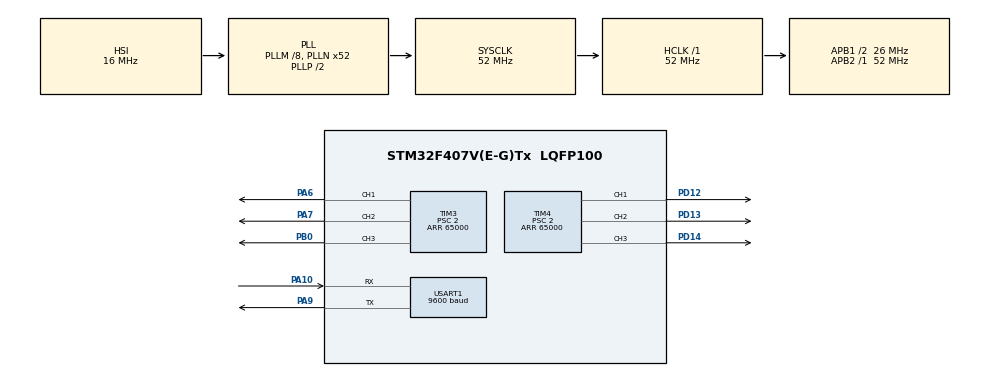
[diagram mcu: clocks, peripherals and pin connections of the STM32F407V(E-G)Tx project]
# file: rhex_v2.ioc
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Mcu.Family=STM32F4
Mcu.Name=STM32F407V(E-G)Tx
Mcu.Package=LQFP100
NVIC.PriorityGroup=NVIC_PRIORITYGROUP_4
PA10.Mode=Asynchronous
PA10.Signal=USART1_RX
PA6.Signal=S_TIM3_CH1
PA7.Signal=S_TIM3_CH2
PA9.Mode=Asynchronous
PA9.Signal=USART1_TX
PB0.Signal=S_TIM3_CH3
PD12.Signal=S_TIM4_CH1
PD13.Signal=S_TIM4_CH2
PD14.Signal=S_TIM4_CH3
PH0-OSC_IN.Mode=HSE-External-Oscillator
PH0-OSC_IN.Signal=RCC_OSC_IN
PH1-OSC_OUT.Mode=HSE-External-Oscillator
PH1-OSC_OUT.Signal=RCC_OSC_OUT
ProjectManager.HeapSize=0x200
ProjectManager.StackSize=0x400
ProjectManager.TargetToolchain=TrueSTUDIO
RCC.48MHZClocksFreq_Value=26000000
RCC.AHBFreq_Value=52000000
RCC.APB1CLKDivider=RCC_HCLK_DIV2
RCC.APB1Freq_Value=26000000
RCC.APB1TimFreq_Value=52000000
RCC.APB2Freq_Value=52000000
RCC.APB2TimFreq_Value=52000000
RCC.CortexFreq_Value=52000000
RCC.HCLKFreq_Value=52000000
RCC.HSE_VALUE=25000000
RCC.HSI_VALUE=16000000
RCC.LSE_VALUE=32768
RCC.PLLM=8
RCC.PLLN=52
RCC.SYSCLKFreq_VALUE=52000000
RCC.SYSCLKSource=RCC_SYSCLKSOURCE_PLLCLK
RCC.VCOOutputFreq_Value=104000000
SH.S_TIM3_CH1.0=TIM3_CH1,PWM Generation1 CH1
SH.S_TIM3_CH2.0=TIM3_CH2,PWM Generation2 CH2
SH.S_TIM3_CH3.0=TIM3_CH3,PWM Generation3 CH3
SH.S_TIM4_CH1.0=TIM4_CH1,PWM Generation1 CH1
SH.S_TIM4_CH2.0=TIM4_CH2,PWM Generation2 CH2
SH.S_TIM4_CH3.0=TIM4_CH3,PWM Generation3 CH3
TIM3.Channel-PWM\ Generation1\ CH1=TIM_CHANNEL_1
TIM3.Channel-PWM\ Generation2\ CH2=TIM_CHANNEL_2
TIM3.Channel-PWM\ Generation3\ CH3=TIM_CHANNEL_3
TIM3.Period=65000
TIM3.Prescaler=2
TIM4.Channel-PWM\ Generation1\ CH1=TIM_CHANNEL_1
TIM4.Channel-PWM\ Generation2\ CH2=TIM_CHANNEL_2
TIM4.Channel-PWM\ Generation3\ CH3=TIM_CHANNEL_3
TIM4.Period=65000
TIM4.Prescaler=2
USART1.BaudRate=9600
USART1.VirtualMode=VM_ASYNC
VP_TIM3_VS_ClockSourceINT.Mode=Internal
VP_TIM4_VS_ClockSourceINT.Mode=Internal
board=rhex_v2

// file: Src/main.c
/**
  ******************************************************************************
  * File Name          : main.c
  * Description        : Main program body
  ******************************************************************************
  ** This notice applies to any and all portions of this file
  * that are not between comment pairs USER CODE BEGIN and
  * USER CODE END. Other portions of this file, whether
  * inserted by the user or by software development tools
  * are owned by their respective copyright owners.
  *
  * COPYRIGHT(c) 2018 STMicroelectronics
  */

#include "main.h"
#include "stm32f4xx_hal.h"
#include "servolib.h"

TIM_HandleTypeDef htim3;
TIM_HandleTypeDef htim4;

UART_HandleTypeDef huart1;

/* USER CODE BEGIN PV */
/* Private variables ---------------------------------------------------------*/

/* USER CODE END PV */

void SystemClock_Config(void);
static void MX_GPIO_Init(void);
static void MX_TIM3_Init(void);
static void MX_TIM4_Init(void);
static void MX_USART1_UART_Init(void);
void HAL_TIM_MspPostInit(TIM_HandleTypeDef *htim);

/* USER CODE BEGIN PFP */
/* Private function prototypes -----------------------------------------------*/

/* USER CODE END PFP */

int main(void)
{

  /* MCU Configuration----------------------------------------------------------*/

  /* Reset of all peripherals, Initializes the Flash interface and the Systick. */
  HAL_Init();

  /* Configure the system clock */
  SystemClock_Config();

  /* Initialize all configured peripherals */
  MX_GPIO_Init();
  MX_TIM3_Init();
  MX_TIM4_Init();
  MX_USART1_UART_Init();

  /* USER CODE BEGIN 2 */

  struct Servos servos;
  initServos(&servos, &htim3, &htim4, 65000);

  /* USER CODE END 2 */

  /* Infinite loop */
  /* USER CODE BEGIN WHILE */
  /* ---------------------------------------------------------- While ---------------------------------------------------------- */
  while (1)
  {
  /* USER CODE END WHILE */

  }

}

/** System Clock Configuration
*/
void SystemClock_Config(void)
{

  RCC_OscInitTypeDef RCC_OscInitStruct;
  RCC_ClkInitTypeDef RCC_ClkInitStruct;

    /**Configure the main internal regulator output voltage
    */
  __HAL_RCC_PWR_CLK_ENABLE();

  __HAL_PWR_VOLTAGESCALING_CONFIG(PWR_REGULATOR_VOLTAGE_SCALE1);

    /**Initializes the CPU, AHB and APB busses clocks
    */
  RCC_OscInitStruct.OscillatorType = RCC_OSCILLATORTYPE_HSI;
  RCC_OscInitStruct.HSIState = RCC_HSI_ON;
  RCC_OscInitStruct.HSICalibrationValue = 16;
  RCC_OscInitStruct.PLL.PLLState = RCC_PLL_ON;
  RCC_OscInitStruct.PLL.PLLSource = RCC_PLLSOURCE_HSI;
  RCC_OscInitStruct.PLL.PLLM = 8;
  RCC_OscInitStruct.PLL.PLLN = 52;
  RCC_OscInitStruct.PLL.PLLP = RCC_PLLP_DIV2;
  RCC_OscInitStruct.PLL.PLLQ = 4;
  if (HAL_RCC_OscConfig(&RCC_OscInitStruct) != HAL_OK)
  {
    _Error_Handler(__FILE__, __LINE__);
  }

    /**Initializes the CPU, AHB and APB busses clocks
    */
  RCC_ClkInitStruct.ClockType = RCC_CLOCKTYPE_HCLK|RCC_CLOCKTYPE_SYSCLK
                              |RCC_CLOCKTYPE_PCLK1|RCC_CLOCKTYPE_PCLK2;
  RCC_ClkInitStruct.SYSCLKSource = RCC_SYSCLKSOURCE_PLLCLK;
  RCC_ClkInitStruct.AHBCLKDivider = RCC_SYSCLK_DIV1;
  RCC_ClkInitStruct.APB1CLKDivider = RCC_HCLK_DIV2;
  RCC_ClkInitStruct.APB2CLKDivider = RCC_HCLK_DIV1;

  if (HAL_RCC_ClockConfig(&RCC_ClkInitStruct, FLASH_LATENCY_1) != HAL_OK)
  {
    _Error_Handler(__FILE__, __LINE__);
  }

    /**Configure the Systick interrupt time
    */
  HAL_SYSTICK_Config(HAL_RCC_GetHCLKFreq()/1000);

    /**Configure the Systick
    */
  HAL_SYSTICK_CLKSourceConfig(SYSTICK_CLKSOURCE_HCLK);

  /* SysTick_IRQn interrupt configuration */
  HAL_NVIC_SetPriority(SysTick_IRQn, 0, 0);
}

/* TIM3 init function */
static void MX_TIM3_Init(void)
{

  TIM_ClockConfigTypeDef sClockSourceConfig;
  TIM_MasterConfigTypeDef sMasterConfig;
  TIM_OC_InitTypeDef sConfigOC;

  htim3.Instance = TIM3;
  htim3.Init.Prescaler = 2;
  htim3.Init.CounterMode = TIM_COUNTERMODE_UP;
  htim3.Init.Period = 65000;
  htim3.Init.ClockDivision = TIM_CLOCKDIVISION_DIV1;
  if (HAL_TIM_Base_Init(&htim3) != HAL_OK)
  {
    _Error_Handler(__FILE__, __LINE__);
  }

  sClockSourceConfig.ClockSource = TIM_CLOCKSOURCE_INTERNAL;
  if (HAL_TIM_ConfigClockSource(&htim3, &sClockSourceConfig) != HAL_OK)
  {
    _Error_Handler(__FILE__, __LINE__);
  }

  if (HAL_TIM_PWM_Init(&htim3) != HAL_OK)
  {
    _Error_Handler(__FILE__, __LINE__);
  }

  sMasterConfig.MasterOutputTrigger = TIM_TRGO_RESET;
  sMasterConfig.MasterSlaveMode = TIM_MASTERSLAVEMODE_DISABLE;
  if (HAL_TIMEx_MasterConfigSynchronization(&htim3, &sMasterConfig) != HAL_OK)
  {
    _Error_Handler(__FILE__, __LINE__);
  }

  sConfigOC.OCMode = TIM_OCMODE_PWM1;
  sConfigOC.Pulse = 0;
  sConfigOC.OCPolarity = TIM_OCPOLARITY_HIGH;
  sConfigOC.OCFastMode = TIM_OCFAST_DISABLE;
  if (HAL_TIM_PWM_ConfigChannel(&htim3, &sConfigOC, TIM_CHANNEL_1) != HAL_OK)
  {
    _Error_Handler(__FILE__, __LINE__);
  }

  if (HAL_TIM_PWM_ConfigChannel(&htim3, &sConfigOC, TIM_CHANNEL_2) != HAL_OK)
  {
    _Error_Handler(__FILE__, __LINE__);
  }

  if (HAL_TIM_PWM_ConfigChannel(&htim3, &sConfigOC, TIM_CHANNEL_3) != HAL_OK)
  {
    _Error_Handler(__FILE__, __LINE__);
  }

  HAL_TIM_MspPostInit(&htim3);

}

/* TIM4 init function */
static void MX_TIM4_Init(void)
{

  TIM_ClockConfigTypeDef sClockSourceConfig;
  TIM_MasterConfigTypeDef sMasterConfig;
  TIM_OC_InitTypeDef sConfigOC;

  htim4.Instance = TIM4;
  htim4.Init.Prescaler = 2;
  htim4.Init.CounterMode = TIM_COUNTERMODE_UP;
  htim4.Init.Period = 65000;
  htim4.Init.ClockDivision = TIM_CLOCKDIVISION_DIV1;
  if (HAL_TIM_Base_Init(&htim4) != HAL_OK)
  {
    _Error_Handler(__FILE__, __LINE__);
  }

  sClockSourceConfig.ClockSource = TIM_CLOCKSOURCE_INTERNAL;
  if (HAL_TIM_ConfigClockSource(&htim4, &sClockSourceConfig) != HAL_OK)
  {
    _Error_Handler(__FILE__, __LINE__);
  }

  if (HAL_TIM_PWM_Init(&htim4) != HAL_OK)
  {
    _Error_Handler(__FILE__, __LINE__);
  }

  sMasterConfig.MasterOutputTrigger = TIM_TRGO_RESET;
  sMasterConfig.MasterSlaveMode = TIM_MASTERSLAVEMODE_DISABLE;
  if (HAL_TIMEx_MasterConfigSynchronization(&htim4, &sMasterConfig) != HAL_OK)
  {
    _Error_Handler(__FILE__, __LINE__);
  }

  sConfigOC.OCMode = TIM_OCMODE_PWM1;
  sConfigOC.Pulse = 0;
  sConfigOC.OCPolarity = TIM_OCPOLARITY_HIGH;
  sConfigOC.OCFastMode = TIM_OCFAST_DISABLE;
  if (HAL_TIM_PWM_ConfigChannel(&htim4, &sConfigOC, TIM_CHANNEL_1) != HAL_OK)
  {
    _Error_Handler(__FILE__, __LINE__);
  }

  if (HAL_TIM_PWM_ConfigChannel(&htim4, &sConfigOC, TIM_CHANNEL_2) != HAL_OK)
  {
    _Error_Handler(__FILE__, __LINE__);
  }

  if (HAL_TIM_PWM_ConfigChannel(&htim4, &sConfigOC, TIM_CHANNEL_3) != HAL_OK)
  {
    _Error_Handler(__FILE__, __LINE__);
  }

  HAL_TIM_MspPostInit(&htim4);

}

/* USART1 init function */
static void MX_USART1_UART_Init(void)
{

  huart1.Instance = USART1;
  huart1.Init.BaudRate = 9600;
  huart1.Init.WordLength = UART_WORDLENGTH_8B;
  huart1.Init.StopBits = UART_STOPBITS_1;
  huart1.Init.Parity = UART_PARITY_NONE;
  huart1.Init.Mode = UART_MODE_TX_RX;
  huart1.Init.HwFlowCtl = UART_HWCONTROL_NONE;
  huart1.Init.OverSampling = UART_OVERSAMPLING_16;
  if (HAL_UART_Init(&huart1) != HAL_OK)
  {
    _Error_Handler(__FILE__, __LINE__);
  }

}

/** Configure pins as
        * Analog
        * Input
        * Output
        * EVENT_OUT
        * EXTI
*/
static void MX_GPIO_Init(void)
{

  /* GPIO Ports Clock Enable */
  __HAL_RCC_GPIOH_CLK_ENABLE();
  __HAL_RCC_GPIOA_CLK_ENABLE();
  __HAL_RCC_GPIOB_CLK_ENABLE();
  __HAL_RCC_GPIOD_CLK_ENABLE();

}

void _Error_Handler(char * file, int line)
{
  while(1)
  {
  }
}

/************************ (C) COPYRIGHT STMicroelectronics *****END OF FILE****/
